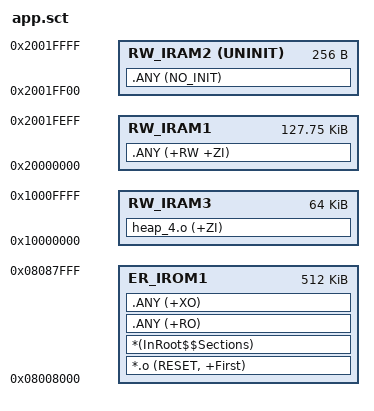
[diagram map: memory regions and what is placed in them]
; *** Scatter-Loading Description File generated by uVision ***
; *************************************************************

LR_IROM1 0x08008000 0x00080000  {    ; load region size_region
  ER_IROM1 0x08008000 0x00080000  {  ; load address = execution address
   *.o (RESET, +First)
   *(InRoot$$Sections)
   .ANY (+RO)
   .ANY (+XO)
  }
  RW_IRAM1 0x20000000 0x0001FF00  {  ; RW data
   .ANY (+RW +ZI)
  }
  RW_IRAM2 0x2001FF00 UNINIT 0x00000100  {
   .ANY (NO_INIT)
  }
  RW_IRAM3 0x10000000 0x00010000  {
    heap_4.o (+ZI)
  }
}
